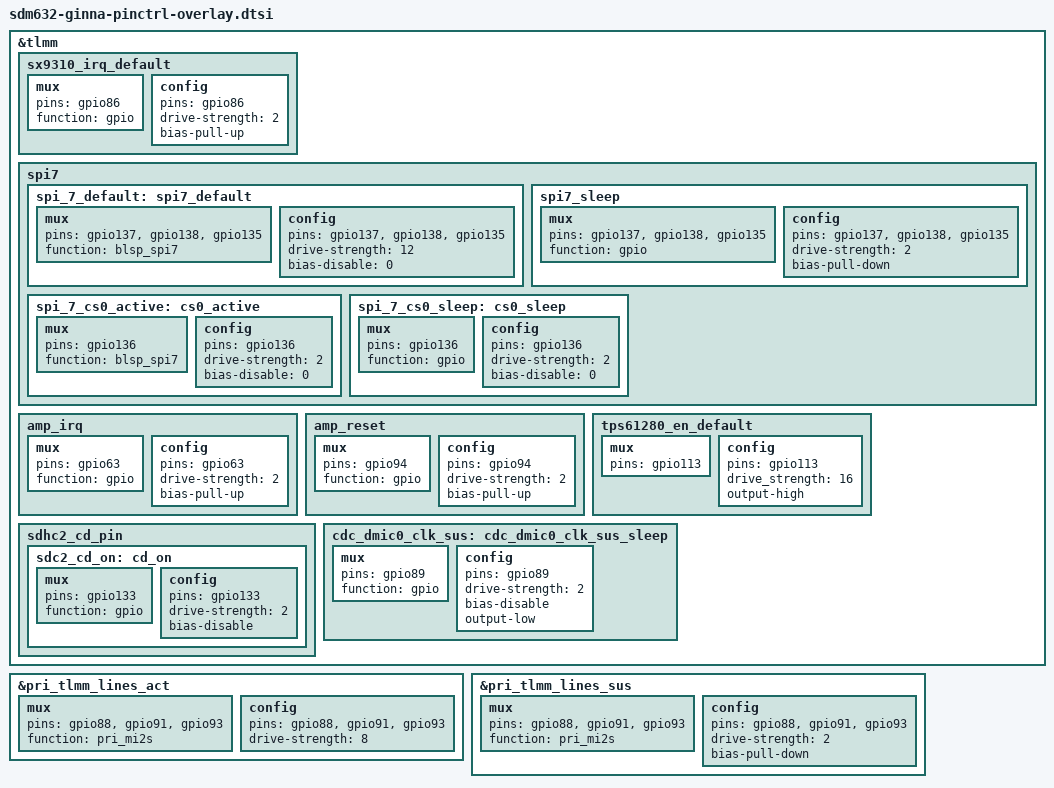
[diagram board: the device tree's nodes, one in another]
/*
 * Copyright (c) 2017-2019, The Linux Foundation. All rights reserved.
 *
 * This program is free software; you can redistribute it and/or modify
 * it under the terms of the GNU General Public License version 2 and
 * only version 2 as published by the Free Software Foundation.
 *
 * This program is distributed in the hope that it will be useful,
 * but WITHOUT ANY WARRANTY; without even the implied warranty of
 * MERCHANTABILITY or FITNESS FOR A PARTICULAR PURPOSE.  See the
 * GNU General Public License for more details.
 */

&tlmm {
	sx9310_irq_default: sx9310_irq_default {
		mux {
			pins = "gpio86";
			function = "gpio";
		};
		config {
			pins = "gpio86";
			drive-strength = <2>;
			bias-pull-up;
		};
	};

	spi7 {
		spi_7_default: spi7_default {
			/* active state */
			mux {
				/* MOSI, MISO, CLK */
				pins = "gpio137", "gpio138", "gpio135";
				function = "blsp_spi7";
			};

			config {
				pins = "gpio137", "gpio138", "gpio135";
				drive-strength = <12>; /* 12 MA */
				bias-disable = <0>; /* No PULL */
			};
		};

		spi7_sleep: spi7_sleep {
			/* suspended state */
			mux {
				/* MOSI, MISO, CLK */
				pins = "gpio137", "gpio138", "gpio135";
				function = "gpio";
			};

			config {
				pins = "gpio137", "gpio138", "gpio135";
				drive-strength = <2>; /* 2 MA */
				bias-pull-down; /* PULL Down */
			};
		};

		spi_7_cs0_active: cs0_active {
			/* CS */
			mux {
				pins = "gpio136";
				function = "blsp_spi7";
			};

			config {
				pins = "gpio136";
				drive-strength = <2>;
				bias-disable = <0>;
			};
		};

		spi_7_cs0_sleep: cs0_sleep {
			/* CS */
			mux {
				pins = "gpio136";
				function = "gpio";
			};

			config {
				pins = "gpio136";
				drive-strength = <2>;
				bias-disable = <0>;
			};
		};
	};

	amp_irq: amp_irq {
		mux {
			pins = "gpio63";
			function = "gpio";
		};
		config {
			pins = "gpio63";
			drive-strength = <2>; /* 2 MA */
			bias-pull-up;
		};
	};

	amp_reset: amp_reset {
		mux {
			pins = "gpio94";
			function = "gpio";
		};
		config {
			pins = "gpio94";
			drive-strength = <2>; /* 2 MA */
			bias-pull-up;
		};
	};

	tps61280_en_default: tps61280_en_default {
		mux {
			pins = "gpio113";
		};
		config {
			pins = "gpio113";
			drive_strength = <16>;
			output-high;
		};
	};

	sdhc2_cd_pin {
		sdc2_cd_on: cd_on {
			mux {
				pins = "gpio133";
				function = "gpio";
			};

			config {
				pins = "gpio133";
				drive-strength = <2>;
				/delete-property/ bias-pull-up;
				bias-disable;
			};
		};
	};

	cdc_dmic0_clk_sus: cdc_dmic0_clk_sus_sleep {
		mux {
			pins = "gpio89";
			function = "gpio";
		};

		config {
			pins = "gpio89";
			drive-strength = <2>;
			bias-disable;
			output-low;
		};
	};
};

&pri_tlmm_lines_act {
	mux {
		pins = "gpio88", "gpio91", "gpio93";
		function = "pri_mi2s";
	};

	config {
		pins = "gpio88", "gpio91", "gpio93";
		drive-strength = <8>;
	};
};

&pri_tlmm_lines_sus {
	mux {
		pins = "gpio88", "gpio91", "gpio93";
		function = "pri_mi2s";
	};

	config {
		pins = "gpio88", "gpio91", "gpio93";
		drive-strength = <2>;
		bias-pull-down;
	};
};
